# AT32UC3A3128S device description
Architecture: AVR32_UC3; Family: AVR UC3
Registers are 32-bit, read-write, reset 0x0 unless marked. A register's access mark holds for its fields unless they carry their own. Offsets are from the block's base; [hi:lo] are bit positions; {n}, {i} and the like mark numbered series; 'fields as' and 'values as' point back to an identical list.

## BUSMON — Bus Monitor module
Instances: BUSMON 0xfffe2800
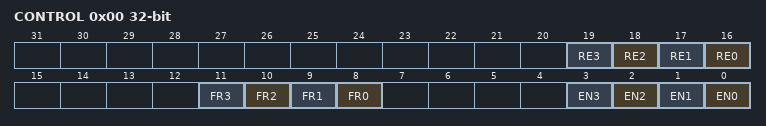
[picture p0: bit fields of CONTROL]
0x00 CONTROL
  [n+16] RE{n} (n=0..3), [n+8] FR{n} (n=0..3), [n] EN{n} (n=0..3)
{0x10+0x10*i} DATA{i} ro (i=0..3) — Data Cycles Channel {i}
{0x14+0x10*i} STALL{i} ro (i=0..3) — Stall Cycles Channel {i}
{0x18+0x10*i} LAT{i} ro (i=0..3) — Max Latency Cycles Channel {i}

## ABDAC — Audio Bitstream DAC
Instances: ABDAC 0xffff4000
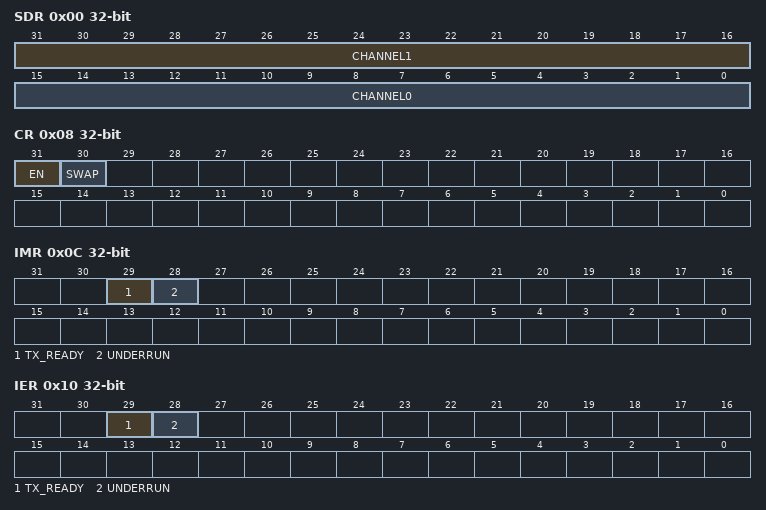
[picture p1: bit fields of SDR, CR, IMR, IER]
0x00 SDR — Sample Data Register
  [31:16] CHANNEL1 — Sample Data for Channel 1
  [15:0] CHANNEL0 — Sample Data for Channel 0
0x08 CR reset not defined — Control Register
  [31] EN — Enable Audio DAC.
  [30] SWAP — Swap Channels
0x0C IMR ro reset not defined — Interrupt Mask Register
  [29] TX_READY — TX Ready Interrupt Mask
  [28] UNDERRUN — Underrun Interrupt Mask
0x10 IER wo reset not defined — Interrupt Enable Register
  [29] TX_READY — TX Ready Interrupt Enable
  [28] UNDERRUN — Underrun Interrupt Enable
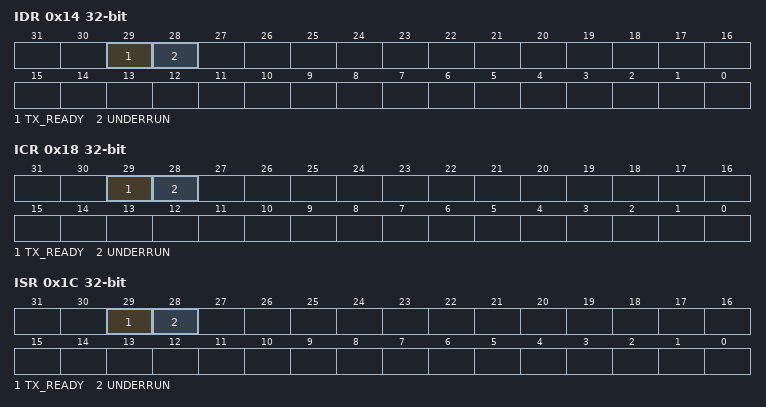
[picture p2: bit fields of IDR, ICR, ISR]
0x14 IDR wo reset not defined — Interupt Disable Register
  [29] TX_READY — TX Ready Interrupt Disable
  [28] UNDERRUN — Underrun Interrupt Disable
0x18 ICR wo reset not defined — Interrupt Clear Register
  [29] TX_READY — TX Ready Interrupt Clear
  [28] UNDERRUN — Underrun Interrupt Clear
0x1C ISR ro reset not defined — Interrupt Status Register
  [29] TX_READY — Interrupt Status Register
  [28] UNDERRUN — Interrupt Status Register

## ECCHRS — Error code corrector Hamming and Reed Solomon
Instances: ECCHRS 0xfffe2400
0x00 CTRL wo
  [0] RST — RST bit(s)
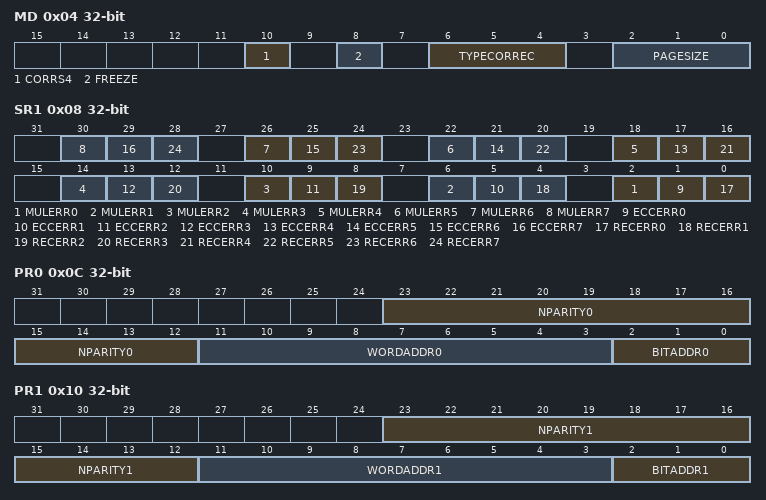
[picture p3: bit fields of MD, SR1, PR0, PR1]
0x04 MD
  [10] CORRS4 — CORRS4 bit(s)
  [8] FREEZE — FREEZE bit(s)
  [6:4] TYPECORREC — TYPECORREC bit(s)
  [2:0] PAGESIZE — PAGESIZE bit(s)
0x08 SR1 ro
  [4n+2] MULERR{n} (n=0..7) — MULERR{n} bit(s)
  [4n+1] ECCERR{n} (n=0..7) — ECCERR{n} bit(s)
  [4n] RECERR{n} (n=0..7) — RECERR{n} bit(s)
0x0C PR0 ro
  [23:12] NPARITY0 — NPARITY0 bit(s)
  [11:3] WORDADDR0 — WORDADDR0 bit(s)
  [2:0] BITADDR0 — BITADDR0 bit(s)
0x10 PR1 ro
  [23:12] NPARITY1 — NPARITY1 bit(s)
  [11:3] WORDADDR1 — WORDADDR1 bit(s)
  [2:0] BITADDR1 — BITADDR1 bit(s)
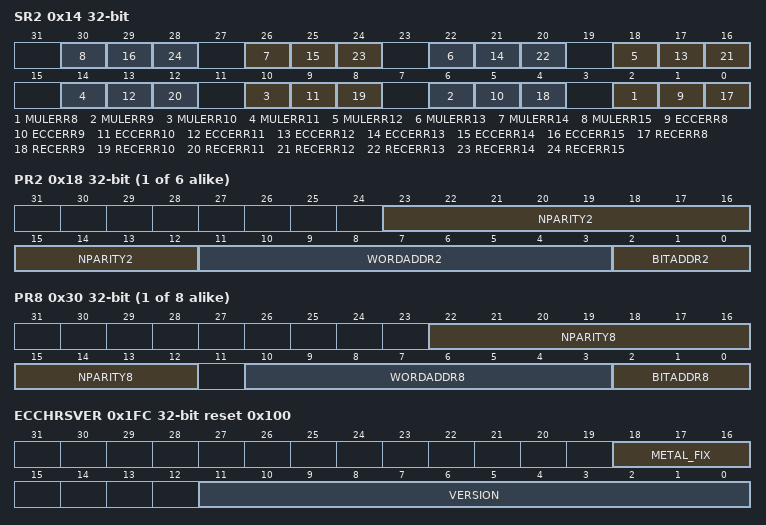
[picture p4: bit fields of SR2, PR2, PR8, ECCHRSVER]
0x14 SR2 ro
  [4n-30] MULERR{n} (n=8..15) — MULERR{n} bit(s)
  [4n-31] ECCERR{n} (n=8..15) — ECCERR{n} bit(s)
  [4n-32] RECERR{n} (n=8..15) — RECERR{n} bit(s)
{0x10+4i} PR{i} ro (i=2..7)
  [23:12] NPARITY{i} — NPARITY{i} bit(s)
  [11:3] WORDADDR{i} — WORDADDR{i} bit(s)
  [2:0] BITADDR{i} — BITADDR{i} bit(s)
{0x10+4i} PR{i} ro (i=8..15)
  [22:12] NPARITY{i} — NPARITY{i} bit(s)
  [10:3] WORDADDR{i} — WORDADDR{i} bit(s)
  [2:0] BITADDR{i} — BITADDR{i} bit(s)
{0x50+4i} CWPS{i:02} ro (i=0..79)
  [7:0] CODEWORD{i:02} — CODEWORD{i:02} bit(s)
{0x190+4i} MDATA{i} ro (i=0..3)
  [9:0] MASKDATA{i} — MASKDATA{i} bit(s)
{0x1A0+4i} ADOFF{i} ro (i=0..3)
  [9:0] OFFSET{i} — OFFSET{i} bit(s)
0x1B0 RS4IER wo
  [0] ENDCOR — ENDCOR bit(s)
0x1B4 RS4IDR wo
  [0] ENDCOR — ENDCOR bit(s)
0x1B8 RS4IMR ro
  [0] ENDCOR — ENDCOR bit(s)
0x1BC RS4ISR ro
  [0] ENDCOR — ENDCOR bit(s)
0x1C0 RS4ISCR wo
  [0] ENDCOR — ENDCOR bit(s)
0x1FC ECCHRSVER ro reset 0x100
  [18:16] METAL_FIX — METAL_FIX bit(s)
  [11:0] VERSION — VERSION bit(s)

## EIC — External Interrupt Controller
Instances: EIC 0xffff0d80
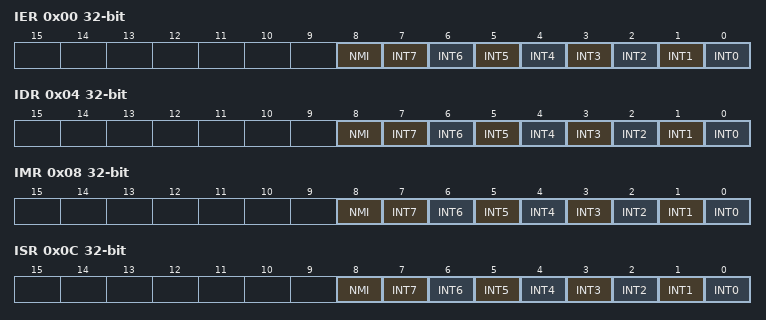
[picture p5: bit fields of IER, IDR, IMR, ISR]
0x00 IER wo — Interrupt Enable Register
  [8] NMI — External Non Maskable CPU interrupt
  [n] INT{n} (n=0..7) — External Interrupt {n}
0x04 IDR wo — Interrupt Disable Register
  fields as IER
0x08 IMR ro — Interrupt Mask Register
  fields as IER
0x0C ISR ro — Interrupt Status Register
  fields as IER
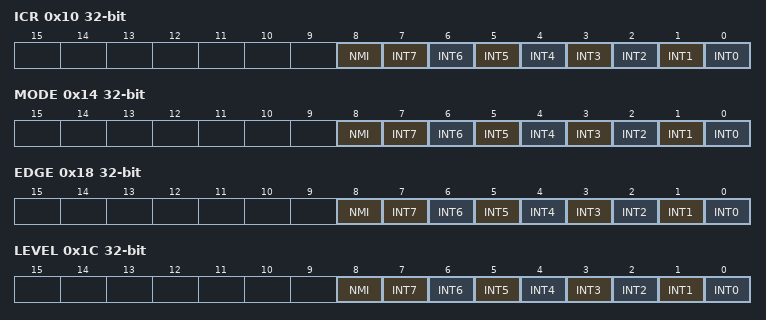
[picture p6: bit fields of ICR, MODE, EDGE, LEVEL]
0x10 ICR wo — Interrupt Clear Register
  fields as IER
0x14 MODE
  fields as IER
0x18 EDGE
  fields as IER
0x1C LEVEL
  fields as IER
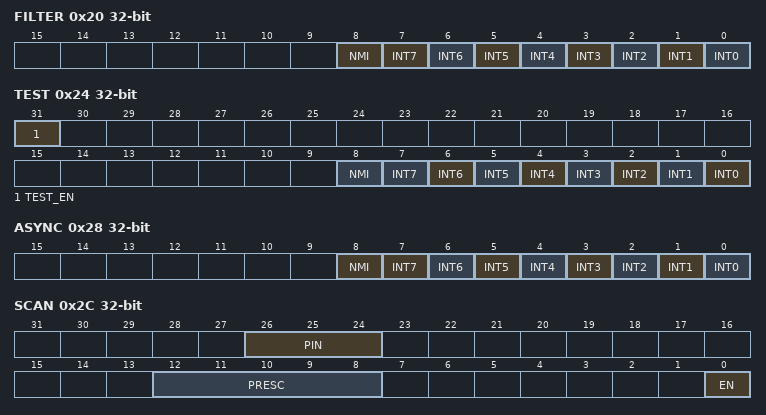
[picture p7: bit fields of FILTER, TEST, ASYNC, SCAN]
0x20 FILTER
  fields as IER
0x24 TEST
  [31] TEST_EN — Test Enable
  [8] NMI — External Non Maskable CPU interrupt
  [n] INT{n} (n=0..7) — External Interrupt {n}
0x28 ASYNC — Asynchronous Mode Register
  fields as IER
0x2C SCAN
  [26:24] PIN — SCAN Pin
  [12:8] PRESC — SCAN Prescale
  [0] EN — SCAN Enable
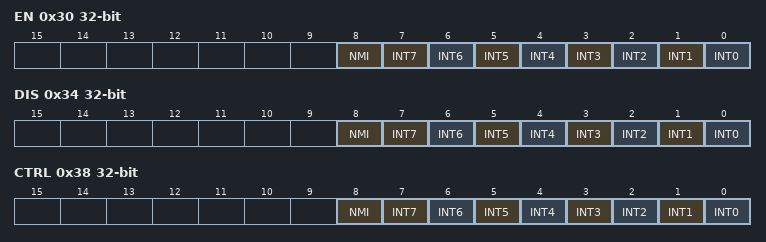
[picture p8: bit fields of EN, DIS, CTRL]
0x30 EN wo — Enable Register
  fields as IER
0x34 DIS wo — Disable Register
  fields as IER
0x38 CTRL — Control Register
  fields as IER
